# NANO103AE_v1 register map
File version: 1.0
Registers are 32-bit, read-write, reset 0x0 unless marked. A register's access mark holds for its fields unless they carry their own. Offsets are from the block's base; [hi:lo] are bit positions; lines under a group give offsets from that group; {n}, {i} and the like mark numbered series; 'fields as' and 'values as' point back to an identical list.

## PWM0 — PWM0 Register Map
Base 0x40040000
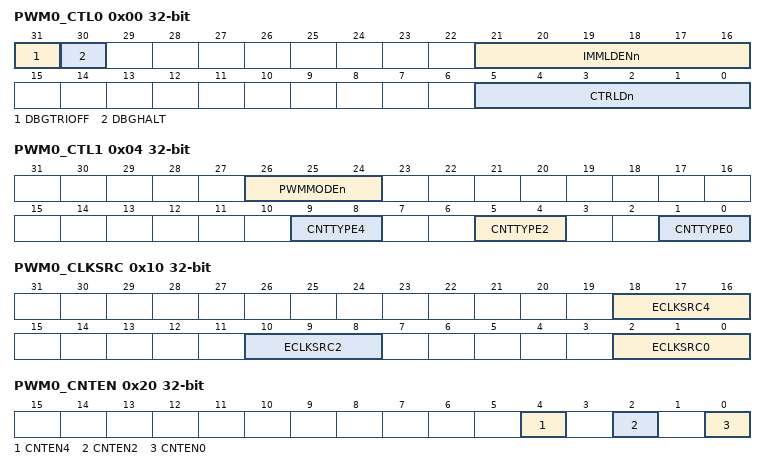
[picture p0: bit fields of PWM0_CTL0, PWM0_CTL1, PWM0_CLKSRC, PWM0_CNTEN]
0x00 PWM0_CTL0 — PWM0 Control Register 0
  [31] DBGTRIOFF — ICE Debug Mode Acknowledge Disable Bit (Write Protect). PWM0 pin will keep output no matter ICE debug mode acknowledged or not. Note: This bit is write protected. Refer toSYS_REGLCTL register.
    0=ICE debug mode acknowledgement effects PWM0 output; 1=ICE debug mode acknowledgement disabled
  [30] DBGHALT — ICE Debug Mode Counter Halt (Write Protect). If counter halt is enabled, PWM0 all counters will keep current value until exit ICE debug mode. Note:This bit is write protected. Refer toSYS_REGLCTL register.
    0=ICE debug mode counter halt Disabled; 1=ICE debug mode counter halt Enabled
  [21:16] IMMLDENn — Immediately Load Enable Bits. Each bit n controls the corresponding PWM0 channel n. Note: If IMMLDENn is enabled, WINLDENn and CTRLDn will be invalid.
    0=PERIOD will load to PBUF at the end point of each period. CMPDAT will load to CMPBUF at the end point or center point of each period by setting CTRLD bit; 1=PERIOD/CMPDAT will load to PBUF and CMPBUF immediately when software update PERIOD/CMPDAT
  [5:0] CTRLDn — Center Re-load. Each bit n controls the corresponding PWM0 channel n. In up-down counter type, PERIOD will load to PBUF at the end point of each period. CMPDAT will load to CMPBUF at the center point of a period.
0x04 PWM0_CTL1 — PWM0 Control Register 1
  [26:24] PWMMODEn — PWM0 Mode. Each bit n controls the corresponding PWM0 channel n. Note: When operating in group function, these bits must all set to the same mode.
    0=PWM0 independent mode; 1=PWM0 complementary mode
  [9:8] CNTTYPE4 — PWM0 Counter Behavior Type 4. Each bit n controls corresponding PWM0 channel n.
    0=Up counter type (supports in capture mode); 1=Down count type (supports in capture mode); 2=Up-down counter type
  [5:4] CNTTYPE2 — PWM0 Counter Behavior Type 2. Each bit n controls corresponding PWM0 channel n.
    values as CNTTYPE4
  [1:0] CNTTYPE0 — PWM0 Counter Behavior Type 0. Each bit n controls corresponding PWM0 channel n.
    values as CNTTYPE4
0x10 PWM0_CLKSRC — PWM0 Clock Source Register
  [all] fields
    0=PWMx_CLK, x denotes 0 or 1; {v}=TIMER{v-1} overflow (v=1..4)
  [18:16] ECLKSRC4 — PWM0_CH45 External Clock Source Select
  [10:8] ECLKSRC2 — PWM0_CH23 External Clock Source Select
  [2:0] ECLKSRC0 — PWM0_CH01 External Clock Source Select
0x14 PWM0_CLKPSC0_1 — PWM0 Clock Pre-Scale Register 0_1
  [11:0] CLKPSC — PWM0 Counter Clock Pre-scale. The clock of PWM0 counter is decided by clock prescaler. Each PWM0 pair share one PWM0 counter clock prescaler. The clock of PWM0 counter is divided by (CLKPSC+ 1).
0x18 PWM0_CLKPSC2_3 — PWM0 Clock Pre-Scale Register 2_3
  fields as PWM0_CLKPSC0_1
0x1C PWM0_CLKPSC4_5 — PWM0 Clock Pre-Scale Register 4_5
  fields as PWM0_CLKPSC0_1
0x20 PWM0_CNTEN — PWM0 Counter Enable Register
  [4] CNTEN4 — PWM0 Counter Enable Bit4
    0=PWM0 Counter4_5 and clock prescaler4 Stop Running. ....; 1=PWM0 Counter4_5 and clock prescaler4 Start Running
  [2] CNTEN2 — PWM0 Counter Enable Bit 2
    0=PWM0 Counter2_3 and clock prescaler2 Stop Running; 1=PWM0 Counter2_3 and clock prescaler2 Start Running
  [0] CNTEN0 — PWM0 Counter Enable Bit 0
    0=PWM0 Counter0_1 and clock prescaler0 Stop Running; 1=PWM0 Counter0_1 and clock prescaler0 Start Running
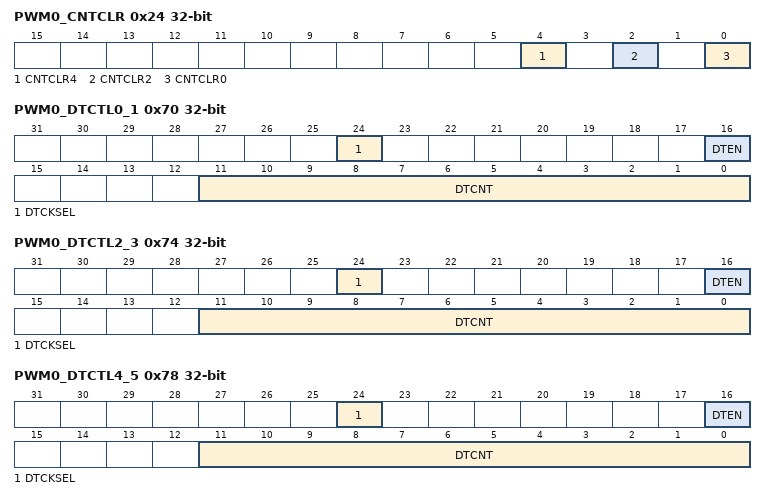
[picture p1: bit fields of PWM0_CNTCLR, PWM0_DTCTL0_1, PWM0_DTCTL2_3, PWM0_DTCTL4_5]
0x24 PWM0_CNTCLR — PWM0 Clear Counter Register
  [all] fields
    0=No effect; 1=Clear 16-bit PWM0 counter to 0000H
  [4] CNTCLR4 — Clear PWM0 Counter Control Bit 4. It is automatically cleared by hardware.
  [2] CNTCLR2 — Clear PWM0 Counter Control Bit 2. It is automatically cleared by hardware.
  [0] CNTCLR0 — Clear PWM0 Counter Control Bit 0. It is automatically cleared by hardware.
0x30 PWM0_PERIOD0 — PWM0 Period Register 0
  [15:0] PERIOD — PWM0 Period Register. Up-Count mode: In this mode, PWM0 counter counts from 0 to PERIOD, and restarts from 0. Down-Count mode: In this mode, PWM0 counter counts from PERIOD to 0, and restarts from PERIOD.
0x38 PWM0_PERIOD2 — PWM0 Period Register 2
  fields as PWM0_PERIOD0
0x40 PWM0_PERIOD4 — PWM0 Period Register 4
  fields as PWM0_PERIOD0
{0x50+4i} PWM0_CMPDAT{i} (i=0..5) — PWM0 Comparator Register {i}
  [15:0] CMPDAT — PWM0 Comparator Register. CMPDAT use to compare with CNTR to generate PWM0 waveform, interrupt and trigger ADC. In independent mode, CMPDAT0~5 denote as 6 independent PWM0_CH0~5 compared point. In complementary mode, CMPDAT0, 2, 4 denote as first compared point, and CMPDAT1, 3, 5 denote as second compared point for the corresponding 3 complementary pairs PWM0_CH0 and PWM0_CH1, PWM0_CH2 and PWM0_CH3, PWM0_CH4 and PWM0_CH5.
0x70 PWM0_DTCTL0_1 — PWM0 Dead-Time Control Register 0_1
  [24] DTCKSEL — Dead-time Clock Select (Write Protect). Note:This register is write protected. Refer toREGWRPROT register.
    0=Dead-time clock source from PWM0_CLKn; 1=Dead-time clock source from prescaler output
  [16] DTEN — Enable Dead-time Insertion for PWM0 Pair (PWM0_CH0, PWM0_CH1)(PWM0_CH2, PWM0_CH3)(PWM0_CH4, PWM0_CH5)(Write Protect). Dead-time insertion is only active when this PWM0 pair complementary mode is enabled. If dead- time insertion is inactive, the outputs of pin pair are complementary without any delay. Note:This register is write protected. Refer toSYS_REGLCTL register.
    0=Dead-time insertion Disabled on the pin pair; 1=Dead-time insertion Enabled on the pin pair
  [11:0] DTCNT — Dead-time Counter (Write Protect). The dead-time can be calculated from the following formula: Note:This register is write protected. Refer toSYS_REGLCTL register.
0x74 PWM0_DTCTL2_3 — PWM0 Dead-Time Control Register 2_3
  fields as PWM0_DTCTL0_1
0x78 PWM0_DTCTL4_5 — PWM0 Dead-Time Control Register 4_5
  fields as PWM0_DTCTL0_1
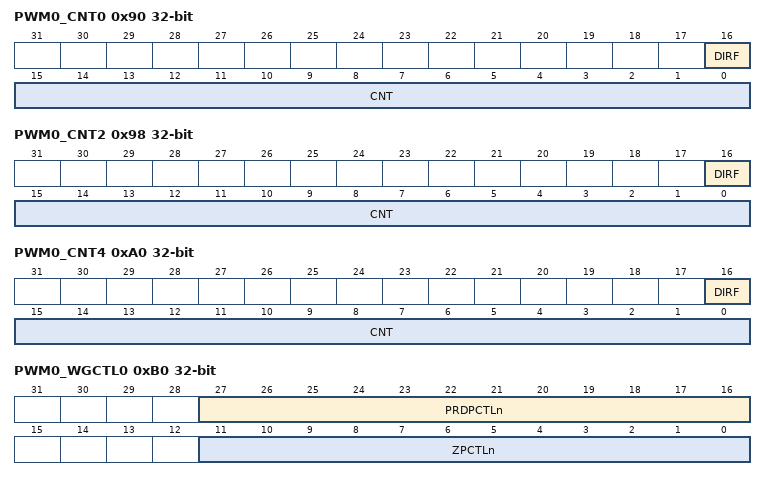
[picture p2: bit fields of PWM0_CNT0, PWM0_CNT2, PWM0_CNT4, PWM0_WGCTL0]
0x90 PWM0_CNT0 ro — PWM0 Counter Register 0
  [16] DIRF — PWM0 Direction Indicator Flag (Read Only)
    0=Counter is Down count; 1=Counter is UP count
  [15:0] CNT — PWM0 Data Register(Read Only). User can monitor CNTR to know the current value in 16-bit period counter.
0x98 PWM0_CNT2 ro — PWM0 Counter Register 2
  fields as PWM0_CNT0
0xA0 PWM0_CNT4 ro — PWM0 Counter Register 4
  fields as PWM0_CNT0
0xB0 PWM0_WGCTL0 — PWM0Waveform Generation Control Register 0
  [27:16] PRDPCTLn — PWM0 Period (Center) Point Control. Each bit n controls the corresponding PWM0 channel n. PWM0 can control output level when PWM0 counter count to (PERIODn+1). Note: This bit is center point control when PWM0 counter operating in up-down counter type.
    0=Do nothing; 1=PWM0 period (center) point output Low; 2=PWM0 period (center) point output High; 3=PWM0 period (center) point output Toggle
  [11:0] ZPCTLn — PWM0 Zero Point Control. Each bit n controls the corresponding PWM0 channel n. PWM0 can control output level when PWM0 counter count to zero.
    0=Do nothing; 1=PWM0 zero point output Low; 2=PWM0 zero point output High; 3=PWM0 zero point output Toggle
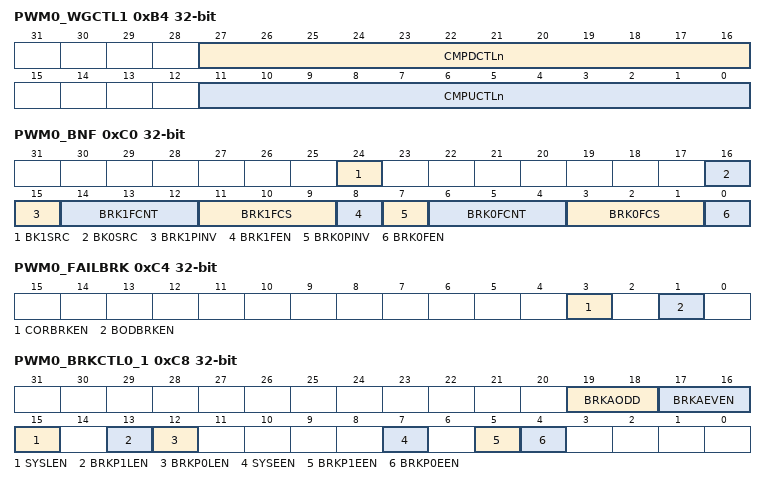
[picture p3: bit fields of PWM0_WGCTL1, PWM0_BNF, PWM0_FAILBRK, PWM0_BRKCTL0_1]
0xB4 PWM0_WGCTL1 — PWM0Waveform Generation Control Register 1
  [27:16] CMPDCTLn — PWM0 Compare Down Point Control. Each bit n controls the corresponding PWM0 channel n. PWM0 can control output level when PWM0 counter down count to CMPDAT. Note: In complementary mode, CMPDCTL1, 3, 5 use as another CMPDCTL for channel 0, 2, 4.
    0=Do nothing; 1=PWM0 compare down point output Low; 2=PWM0 compare down point output High; 3=PWM0 compare down point output Toggle
  [11:0] CMPUCTLn — PWM0 Compare Up Point Control. Each bit n controls the corresponding PWM0 channel n. PWM0 can control output level when PWM0 counter up count to CMPDAT. Note: In complementary mode, CMPUCTL1, 3, 5 use as another CMPUCTL for channel 0, 2, 4.
    0=Do nothing; 1=PWM0 compare up point output Low; 2=PWM0 compare up point output High; 3=PWM0 compare up point output Toggle
0xB8 PWM0_MSKEN — PWM0 Mask Enable Register
  [5:0] MSKENn — PWM0 Mask Enable Bits. Each bit n controls the corresponding PWM0 channel n. The PWM0 output signal will be masked when this bit is enabled. The corresponding PWM0 channel n will output MSKDATn (PWM0_MSK[5:0]) data.
    0=PWM0 output signal is non-masked; 1=PWM0 output signal is masked and output MSKDATn data
0xBC PWM0_MSK — PWM0 Mask Data Register
  [5:0] MSKDATn — PWM0 Mask Data Bits. This data bit control the state of PWM0_CHn output pin, if corresponding mask function is enabled.
    0=Output logic low to PWM0_CHn; 1=Output logic high to PWM0_CHn
0xC0 PWM0_BNF — PWM0 Brake Noise Filter Register
  [24] BK1SRC — Brake 1 Pin Source Select. For PWM0 setting:
    0=Brake 1 pin source come from PWM0_BRAKE1. Brake 1 pin source come from PWM1_BRAKE1; 1=Brake 1 pin source come from PWM1_BRAKE1. Brake 1 pin source come from PWM0_BRAKE1
  [16] BK0SRC — Brake 0 Pin Source Select. For PWM0 setting:
    0=Brake 0 pin source come from PWM0_BRAKE0. Brake 0 pin source come from PWM1_BRAKE0; 1=Brake 0 pin source come from PWM1_BRAKE0. Brake 0 pin source come from PWM0_BRAKE0
  [15] BRK1PINV — Brake 1 Pin Inverse
    0=The state of pin PWMx_BRAKE1 is passed to the negative edge detector; 1=The inversed state of pin PWMx_BRAKE1 is passed to the negative edge detector
  [14:12] BRK1FCNT — Brake 1 Edge Detector Filter Count. The register bits control the Brake1 filter counter to count from 0 to BRK1FCNT.
  [11:9] BRK1FCS — Brake 1 Edge Detector Filter Clock Selection
    0=Filter clock = HCLK; 1=Filter clock = HCLK/2; 2=Filter clock = HCLK/4; 3=Filter clock = HCLK/8; 4=Filter clock = HCLK/16; 5=Filter clock = HCLK/32; 6=Filter clock = HCLK/64; 7=Filter clock = HCLK/128
  [8] BRK1FEN — PWM0 Brake 1 Noise Filter Enable Bit
    0=Noise filter of PWM0 Brake 1 Disabled; 1=Noise filter of PWM0 Brake 1 Enabled
  [7] BRK0PINV — Brake 0 Pin Inverse
    0=The state of pin PWMx_BRAKE0 is passed to the negative edge detector; 1=The inversed state of pin PWMx_BRAKE10 is passed to the negative edge detector
  [6:4] BRK0FCNT — Brake 0 Edge Detector Filter Count. The register bits control the Brake0 filter counter to count from 0 to BRK1FCNT.
  [3:1] BRK0FCS — Brake 0 Edge Detector Filter Clock Selection
    values as BRK1FCS
  [0] BRK0FEN — PWM0 Brake 0 Noise Filter Enable Bit
    0=Noise filter of PWM0 Brake 0 Disabled; 1=Noise filter of PWM0 Brake 0 Enabled
0xC4 PWM0_FAILBRK — PWM0 System Fail Brake Control Register
  [3] CORBRKEN — Core Lockup Detection Trigger PWM0 Brake Function 0 Enable Bit
    0=Brake Function triggered by Core lockup detection Disabled; 1=Brake Function triggered by Core lockup detection Enabled
  [1] BODBRKEN — Brown-out Detection Trigger PWM0 Brake Function 0 Enable Bit
    0=Brake Function triggered by BOD Disabled; 1=Brake Function triggered by BOD Enabled
0xC8 PWM0_BRKCTL0_1 — PWM0 Brake Edge Detect Control Register 0_1
  [19:18] BRKAODD — PWM0 Brake Action Select for Odd Channel (Write Protect). Note: This register is write protected. Refer toSYS_REGLCTL register.
    0=PWM0 odd channel brake function not affect channel output; 1=PWM0 odd channel output tri-state when brake happened; 2=PWM0 odd channel output low level whenbrake happened; 3=PWM0 odd channel output high level when brake happened
  [17:16] BRKAEVEN — PWM0 Brake Action Select for Even Channel (Write Protect). Note: This register is write protected. Refer toSYS_REGLCTL register.
    0=PWM0 even channelbrake function not affect channel output; 1=PWM0 even channel output tri-state when brake happened; 2=PWM0 even channel output low level whenbrake happened; 3=PWM0 even channel output high level when brake happened
  [15] SYSLEN — Enable System Fail As Level-detect Brake Source(Write Protect). Note: This register is write protected. Refer toSYS_REGLCTL register.
    0=System Fail condition as level-detect brake source Disabled; 1=System Fail condition as level-detect brake source Enabled
  [13] BRKP1LEN — Enable BKP1 Pin As Level-detect Brake Source(Write Protect). Note: This register is write protected. Refer toSYS_REGLCTL register.
    0=PWMx_BRAKE1 pin as level-detect brake source Disabled; 1=PWMx_BRAKE1 pin as level-detect brake source Enabled
  [12] BRKP0LEN — Enable BKP0 Pin As Level-detect Brake Source(Write Protect). Note: This register is write protected. Refer toSYS_REGLCTL register.
    0=PWMx_BRAKE0 pin as level-detect brake source Disabled; 1=PWMx_BRAKE0 pin as level-detect brake source Enabled
  [7] SYSEEN — Enable System Fail As Edge-detect Brake Source(Write Protect). Note: This register is write protected. Refer toSYS_REGLCTL register.
    0=System Fail condition as edge-detect brake source Disabled; 1=System Fail condition as edge-detect brake source Enabled
  [5] BRKP1EEN — Enable PWMx_BRAKE1 Pin As Edge-detect Brake Source(Write Protect). Note: This register is write protected. Refer toSYS_REGLCTL register.
    0=BKP1 pin as edge-detect brake source Disabled; 1=BKP1 pin as edge-detect brake source Enabled
  [4] BRKP0EEN — Enable PWMx_BRAKE0 Pin As Edge-detect Brake Source(Write Protect). Note: This register is write protected. Refer toSYS_REGLCTL register.
    0=BKP0 pin as edge-detect brake source Disabled; 1=BKP0 pin as edge-detect brake source Enabled
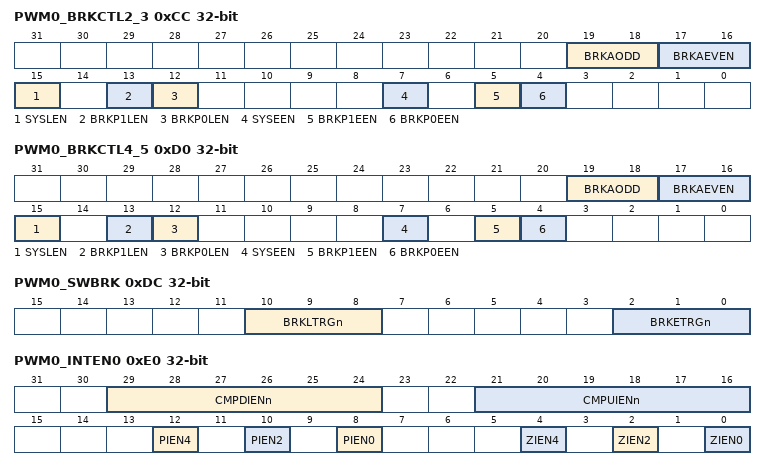
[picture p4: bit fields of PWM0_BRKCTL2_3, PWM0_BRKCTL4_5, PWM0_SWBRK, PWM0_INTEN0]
0xCC PWM0_BRKCTL2_3 — PWM0 Brake Edge Detect Control Register 2_3
  fields as PWM0_BRKCTL0_1
0xD0 PWM0_BRKCTL4_5 — PWM0 Brake Edge Detect Control Register 4_5
  fields as PWM0_BRKCTL0_1
0xD4 PWM0_POLCTL — PWM0 Pin Polar Inverse Register
  [5:0] PINVn — PWM0 PIN Polar Inverse Control. The register controls polarity state of PWM0 output. Each bit n controls the corresponding PWM0 channel n.
    0=PWM0 output polar inverse Disabled; 1=PWM0 output polar inverse Enabled
0xD8 PWM0_POEN — PWM0 Output Enable Register
  [5:0] POENn — PWM0 Pin Output Enable Bits. Each bit n controls the corresponding PWM0 channel n.
    0=PWM0 pin at tri-state; 1=PWM0 pin in output mode
0xDC PWM0_SWBRK wo — PWM0 Software Brake Control Register
  [10:8] BRKLTRGn — PWM0 Level Brake Software Trigger (Write Only)(Write Protect). Each bit n controls the corresponding PWM0 pair n. Write 1 to this bit will trigger level brake, and set BRKLIFn to 1 in PWM0_INTSTS1 register. Note:This register is write protected. Refer toSYS_REGLCTL register.
  [2:0] BRKETRGn — PWM0 Edge Brake Software Trigger (Write Only)(Write Protect). Each bit n controls the corresponding PWM0 pair n. Write 1 to this bit will trigger Edge brake, and set BRKEIFn to 1 in PWM0_INTSTS1 register. Note:This register is write protected. Refer toSYS_REGLCTL register.
0xE0 PWM0_INTEN0 — PWM0 Interrupt Enable Register 0
  [29:24] CMPDIENn — PWM0 Compare Down Count Interrupt Enable Bits. Each bit n controls the corresponding PWM0 channel n. Note: In complementary mode, CMPDIEN1, 3, 5 use as another CMPDIEN for channel 0, 2, 4.
    0=Compare down count interrupt Disabled; 1=Compare down count interrupt Enabled
  [21:16] CMPUIENn — PWM0 Compare Up Count Interrupt Enable Bits. Each bit n controls the corresponding PWM0 channel n. Note: In complementary mode, CMPUIEN1, 3, 5 use as another CMPUIEN for channel 0, 2, 4.
    0=Compare up count interrupt Disabled; 1=Compare up count interrupt Enabled
  [12] PIEN4 — PWM0 Period Point Interrupt Enable Bit 4. Note: When operating in up-down counter type, period point means center point.
    0=PWM0counter4_5 period point interrupt Disabled; 1=PWM0counter4_5 period point interrupt Enabled
  [10] PIEN2 — PWM0 Period Point Interrupt Enable Bit 2. Note: When operating in up-down counter type, period point means center point.
    0=PWM0counter2_3 period point interrupt Disabled; 1=PWM0counter2_3 period point interrupt Enabled
  [8] PIEN0 — PWM0 Period Point Interrupt Enable Bit 0. Note: When operating in up-down counter type, period point means center point.
    0=PWM0counter0_1 period point interrupt Disabled; 1=PWM0counter0_1 period point interrupt Enabled
  [4] ZIEN4 — PWM0 Zero Point Interrupt Enable Bit 4. Note: Odd channels will read always 0 at complementary mode.
    0=PWM0counter4_5 zero point interrupt Disabled; 1=PWM0counter4_5 zero point interrupt Enabled
  [2] ZIEN2 — PWM0 Zero Point Interrupt Enable Bit 2. Note: Odd channels will read always 0 at complementary mode.
    0=PWM0counter2_3 zero point interrupt Disabled; 1=PWM0counter2_3 zero point interrupt Enabled
  [0] ZIEN0 — PWM0 Zero Point Interrupt Enable Bit 0. Note: Odd channels will read always 0 at complementary mode.
    0=PWM0counter0_1 zero point interrupt Disabled; 1=PWM0counter0_1 zero point interrupt Enabled
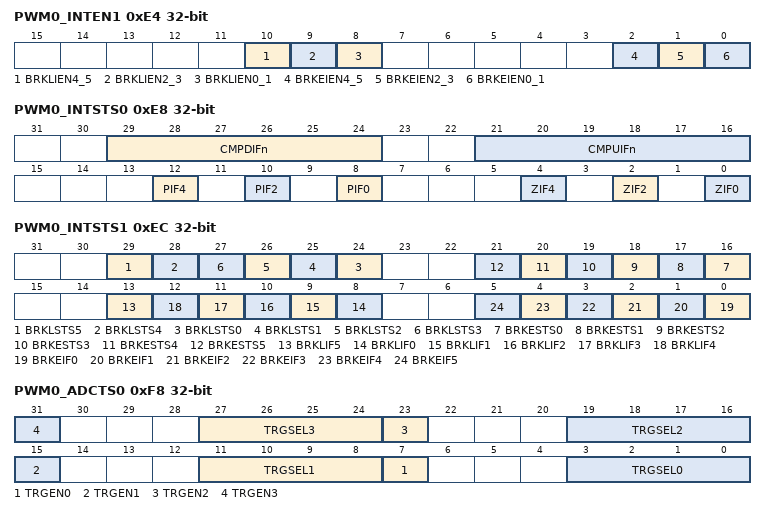
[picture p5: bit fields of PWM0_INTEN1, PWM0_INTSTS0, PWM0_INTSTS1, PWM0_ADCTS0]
0xE4 PWM0_INTEN1 — PWM0 Interrupt Enable Register 1
  [10] BRKLIEN4_5 — PWM0 Level-detect Brake Interrupt Enable Bit for Channel4/5(Write Protect). Note: This register is write protected. Refer toSYS_REGLCTL register.
    0=Level-detect Brake interrupt for channel4/5 Disabled; 1=Level-detect Brake interrupt for channel4/5 Enabled
  [9] BRKLIEN2_3 — PWM0 Level-detect Brake Interrupt Enable Bitfor Channel2/3(Write Protect). Note: This register is write protected. Refer toSYS_REGLCTL register.
    0=Level-detect Brake interrupt for channel2/3 Disabled; 1=Level-detect Brake interrupt for channel2/3 Enabled
  [8] BRKLIEN0_1 — PWM0 Level-detect Brake Interrupt Enable Bitfor Channel0/1(Write Protect). Note: This register is write protected. Refer toSYS_REGLCTL register.
    0=Level-detect Brake interrupt for channel0/1 Disabled; 1=Level-detect Brake interrupt for channel0/1 Enabled
  [2] BRKEIEN4_5 — PWM0 Edge-detect Brake Interrupt Enable Bitfor Channel4/5(Write Protect). Note: This register is write protected. Refer toSYS_REGLCTL register.
    0=Edge-detect Brake interrupt for channel4/5 Disabled; 1=Edge-detect Brake interrupt for channel4/5 Enabled
  [1] BRKEIEN2_3 — PWM0 Edge-detect Brake Interrupt Enable Bitfor Channel2/3(Write Protect). Note: This register is write protected. Refer toSYS_REGLCTL register.
    0=Edge-detect Brake interrupt for channel2/3 Disabled; 1=Edge-detect Brake interrupt for channel2/3 Enabled
  [0] BRKEIEN0_1 — PWM0 Edge-detect Brake Interrupt Enable Bitfor Channel0/1(Write Protect). Note: This register is write protected. Refer toSYS_REGLCTL register.
    0=Edge-detect Brake interrupt for channel0/1 Disabled; 1=Edge-detect Brake interrupt for channel0/1 Enabled
0xE8 PWM0_INTSTS0 — PWM0 Interrupt Flag Register 0
  [29:24] CMPDIFn — PWM0 Compare Down Count Interrupt Flag. Each bit n controls the corresponding PWM0 channel n. Flag is set by hardware when PWM0 counter down count and reaches PWM0_CMPDATn, software can clear this bit by writing 1 to it. Note1: If CMPDAT equal to PERIOD, this flag is not working in down counter type selection. Note2: In complementary mode, CMPDIF1, 3, 5 use as another CMPDIF for channel 0, 2, 4.
  [21:16] CMPUIFn — PWM0 Compare Up Count Interrupt Flag. Flag is set by hardware when PWM0 counter up count and reaches PWM0_CMPDATn, software can clear this bit by writing 1 to it. Each bit n controls the corresponding PWM0 channel n. Note1: If CMPDAT equal to PERIOD, this flag is not working in up counter type selection. Note2: In complementary mode, CMPUIF1, 3, 5 use as another CMPUIF for channel 0, 2, 4.
  [12] PIF4 — PWM0 Period Point Interrupt Flag 4. This bit is set by hardware when PWM0_CH4 counter reaches PWM0_PERIOD4, software can write 1 to clear this bit to zero.
  [10] PIF2 — PWM0 Period Point Interrupt Flag 2. This bit is set by hardware when PWM0_CH2 counter reaches PWM0_PERIOD2, software can write 1 to clear this bit to zero.
  [8] PIF0 — PWM0 Period Point Interrupt Flag 0. This bit is set by hardware when PWM0_CH0 counter reaches PWM0_PERIOD0, software can write 1 to clear this bit to zero.
  [4] ZIF4 — PWM0 Zero Point Interrupt Flag 4. This bit is set by hardware when PWM0_CH4 counter reaches zero, software can write 1 to clear this bit to zero.
  [2] ZIF2 — PWM0 Zero Point Interrupt Flag 2. This bit is set by hardware when PWM0_CH2 counter reaches zero, software can write 1 to clear this bit to zero.
  [0] ZIF0 — PWM0 Zero Point Interrupt Flag 0. This bit is set by hardware when PWM0_CH0 counter reaches zero, software can write 1 to clear this bit to zero.
0xEC PWM0_INTSTS1 — PWM0 Interrupt Flag Register 1
  [29] BRKLSTS5 ro — PWM0 Channel5 Level-detect Brake Status (Read Only). Note: This bit is read only and auto cleared by hardware. When enabled brake source return to high level, PWM0 will release brake state until current PWM0 period finished. The PWM0 waveform will start output from next full PWM0 period.
    0=PWM0 channel5 level-detect brake state is released; 1=When PWM0 channel5 level-detect brake detects a falling edge of any enabled brake source; this flag will be set to indicate the PWM0 channel5 at brake state
  [28] BRKLSTS4 ro — PWM0 Channel4 Level-detect Brake Status (Read Only). Note: This bit is read only and auto cleared by hardware. When enabled brake source return to high level, PWM0 will release brake state until current PWM0 period finished. The PWM0 waveform will start output from next full PWM0 period.
    0=PWM0 channel4 level-detect brake state is released; 1=When PWM0 channel4 level-detect brake detects a falling edgeof any enabled brake source; this flag will be set to indicate the PWM0 channel4 at brake state
  [n+24] BRKLSTS{n} ro (n=0..3) — PWM0 Channel{n} Level-detect Brake Status (Read Only). Note: This bit is read only and auto cleared by hardware. When enabled brake source return to high level, PWM0 will release brake state until current PWM0 period finished. The PWM0 waveform will start output from next full PWM0 period.
    0=PWM0 channel{n} level-detect brake state is released; 1=When PWM0 channel{n} level-detect brake detects a falling edge of any enabled brake source; this flag will be set to indicate the PWM0 channel{n} at brake state
  [n+16] BRKESTS{n} ro (n=0..5) — PWM0 Channel{n} Edge-detect Brake Status (Read Only)
    0=PWM0 channel{n} edge-detect brake state is released; 1=When PWM0 channel{n} edge-detect brake detects a falling edge of any enabled brake source; this flag will be set to indicate the PWM0 channel{n} at brake state, writing 1 to clear
  [13] BRKLIF5 — PWM0 Channel5 Level-detect Brake Interrupt Flag(Write Protect). Note: This bit is write protected. Refer toSYS_REGLCTL register.
    0=PWM0 channel5 level-detect brake event do not happened; 1=When PWM0 channel5 level-detect brake event happened, this bit is set to 1, writing 1 to clear
  [n+8] BRKLIF{n} (n=0..4) — PWM0 Channel{n} Level-detect Brake Interrupt Flag (Write Protect). Note: This bit is write protected. Refer toSYS_REGLCTL register.
    0=PWM0 channel{n} level-detect brake event do not happened; 1=When PWM0 channel{n} level-detect brake event happened, this bit is set to 1, writing 1 to clear
  [n] BRKEIF{n} (n=0..5) — PWM0 Channel{n} Edge-detect Brake Interrupt Flag (Write Protect). Note: This bit is write protected. Refer toSYS_REGLCTL register.
    0=PWM0 channel{n} edge-detect brake event do not happened; 1=When PWM0 channel{n} edge-detect brake event happened, this bit is set to 1, writing 1 to clear
0xF8 PWM0_ADCTS0 — PWM0 Trigger ADC Source Select Register 0
  [8n+7] TRGEN{n} (n=0..3) — PWM0_CH{n} Trigger EADC Enable Bit
    0=PWM0_CH{n} Trigger EADC Disabled; 1=PWM0_CH{n} Trigger EADC Enabled
  [27:24] TRGSEL3 — PWM0_CH3 Trigger ADC Source Select. Others reserved
    0=PWM0_CH2 zero point; 1=PWM0_CH2 period point; 2=PWM0_CH2 zero or period point; 3=PWM0_CH2 up-count CMPDAT point; 4=PWM0_CH2 down-count CMPDAT point; 8=PWM0_CH3 up-count CMPDAT point; 9=PWM0_CH3 down-count CMPDAT point
  [19:16] TRGSEL2 — PWM0_CH2 Trigger ADC Source Select. Others reserved
    values as TRGSEL3
  [11:8] TRGSEL1 — PWM0_CH1 Trigger ADC Source Select. Others reserved
    0=PWM0_CH0 zero point; 1=PWM0_CH0 period point; 2=PWM0_CH0 zero or period point; 3=PWM0_CH0 up-count CMPDAT point; 4=PWM0_CH0 down-count CMPDAT point; 8=PWM0_CH1 up-count CMPDAT point; 9=PWM0_CH1 down-count CMPDAT point
  [3:0] TRGSEL0 — PWM0_CH0 Trigger ADC Source Select. Others reserved
    values as TRGSEL1
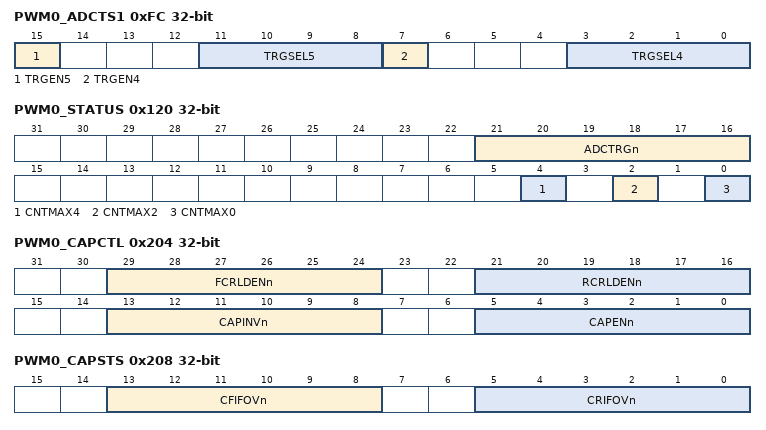
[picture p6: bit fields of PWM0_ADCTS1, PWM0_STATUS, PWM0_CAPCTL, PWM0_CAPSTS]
0xFC PWM0_ADCTS1 — PWM0 Trigger ADC Source Select Register 1
  [15] TRGEN5 — PWM0_CH5 Trigger EADC Enable Bit
    0=PWM0_CH5 Trigger EADC Disabled; 1=PWM0_CH5 Trigger EADC Enabled
  [11:8] TRGSEL5 — PWM0_CH5 Trigger ADC Source Select. Others reserved
    0=PWM0_CH4 zero point; 1=PWM0_CH4 period point; 2=PWM0_CH4 zero or period point; 3=PWM0_CH4 up-count CMPDAT point; 4=PWM0_CH4 down-count CMPDAT point; 8=PWM0_CH5 up-count CMPDAT point; 9=PWM0_CH5 down-count CMPDAT point
  [7] TRGEN4 — PWM0_CH4 Trigger EADC Enable Bit
    0=PWM0_CH4 Trigger EADC Disabled; 1=PWM0_CH4 Trigger EADC Enabled
  [3:0] TRGSEL4 — PWM0_CH4 Trigger ADC Source Select. Others reserved
    values as TRGSEL5
0x120 PWM0_STATUS
  [21:16] ADCTRGn — ADC Start of Conversion Status. Each bit n controls the corresponding PWM0 channel n.
    0=Indicates no ADC start of conversion trigger event has occurred; 1=Indicates an ADC start of conversion trigger event has occurred, software can write 1 to clear this bit
  [4] CNTMAX4 — Time-base Counter 4 Equal to 0xFFFF Latched Status
    0=indicates the time-base counter never reached its maximum value 0xFFFF; 1=indicates the time-base counter reached its maximum value, software can write 1 to clear this bit
  [2] CNTMAX2 — Time-base Counter 2 Equal to 0xFFFF Latched Status
    values as CNTMAX4
  [0] CNTMAX0 — Time-base Counter 0 Equal to 0xFFFF Latched Status
    values as CNTMAX4
0x200 PWM0_CAPINEN — PWM0 Capture Input Enable Register
  [5:0] CAPINENn — Capture Input Enable Bits. Each bit n controls the corresponding PWM0 channel n.
    0=PWM0 Channel capture input path Disabled. The input of PWM0 channel capture function is always regarded as 0; 1=PWM0 Channel capture input path Enabled. The input of PWM0 channel capture function comes from correlative multifunction pin
0x204 PWM0_CAPCTL — PWM0 Capture Control Register
  [29:24] FCRLDENn — Falling Capture Reload EnableBits. Each bit n controls the corresponding PWM0 channel n.
    0=Falling capture reload counter Disabled; 1=Falling capture reload counter Enabled
  [21:16] RCRLDENn — Rising Capture Reload Enable Bits. Each bit n controls the corresponding PWM0 channel n.
    0=Risingcapture reload counter Disabled; 1=Risingcapture reload counter Enabled
  [13:8] CAPINVn — Capture Inverter Enable Bits. Each bit n controls the corresponding PWM0 channel n.
    0=Capture source inverter Disabled; 1=Capture source inverter Enabled. Reverse the input signal from GPIO
  [5:0] CAPENn — Capture Function Enable Bits. Each bit n controls the corresponding PWM0 channel n.
    0=Capture function Disabled. RCAPDAT/FCAPDAT register will not be updated; 1=Capture function Enabled. Capture latched the PWM0 counter value when detected rising or falling edge of input signal and saved to RCAPDAT (Rising latch) and FCAPDAT (Falling latch)
0x208 PWM0_CAPSTS ro — PWM0 Capture Status Register
  [13:8] CFIFOVn — Capture Falling Interrupt Flag Overrun Status(Read Only). This flag indicatesif falling latch happenedwhen the corresponding CAPFIFis 1. Each bit n controls the corresponding PWM0 channel n. Note:This bit will be cleared automatically when user clear corresponding CAPFIF.
  [5:0] CRIFOVn — Capture Rising Interrupt Flag Overrun Status(Read Only). This flag indicatesif rising latch happenedwhen the corresponding CAPRIFis 1. Each bit n controls the corresponding PWM0 channel n. Note:This bit will be cleared automatically when user clear corresponding CAPRIF.
{0x20C+8i} PWM0_RCAPDAT{i} ro (i=0..5) — PWM0 Rising Capture Data Register {i}
  [15:0] RCAPDAT — PWM0 Rising Capture Data Register(Read Only). When rising capture condition happened, the PWM0 counter value will be saved in this register.
{0x210+8i} PWM0_FCAPDAT{i} ro (i=0..5) — PWM0 Falling Capture Data Register {i}
  [15:0] FCAPDAT — PWM0 Falling Capture Data Register(Read Only). When falling capture condition happened, the PWM0 counter value will be saved in this register.
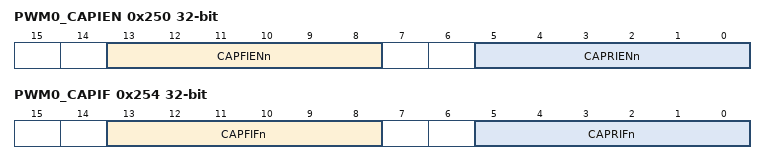
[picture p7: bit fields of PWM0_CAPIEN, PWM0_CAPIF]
0x250 PWM0_CAPIEN — PWM0 Capture Interrupt Enable Register
  [13:8] CAPFIENn — PWM0 Capture Falling Latch Interrupt Enable Bits. Each bit n controls the corresponding PWM0 channel n.
    0=Capture falling edge latch interrupt Disabled; 1=Capture falling edge latch interrupt Enabled
  [5:0] CAPRIENn — PWM0 Capture Rising Latch Interrupt Enable Bits. Each bit n controls the corresponding PWM0 channel n.
    0=Capture rising edge latch interrupt Disabled; 1=Capture rising edge latch interrupt Enabled
0x254 PWM0_CAPIF — PWM0 Capture Interrupt Flag Register
  [13:8] CAPFIFn — PWM0 Capture Falling Latch Interrupt Flag. This bit is writing 1 to clear. Each bit n controls the corresponding PWM0 channel n.
    0=No capture falling latch condition happened; 1=Capture falling latch condition happened, this flag will be set to high
  [5:0] CAPRIFn — PWM0 Capture Rising Latch Interrupt Flag. This bit is writing 1 to clear. Each bit n controls the corresponding PWM0 channel n.
    0=No capture rising latch condition happened; 1=Capture rising latch condition happened, this flag will be set to high
0x300 PWM0_SELFTEST — PWM0 Self-test Mode Enable
0x304 PWM0_PBUF0 ro — PWM0 PERIOD0 Buffer
  [15:0] PBUF — PWM0 Period Register Buffer(Read Only). Used as PERIOD active register.
0x30C PWM0_PBUF2 ro — PWM0 PERIOD2 Buffer
  fields as PWM0_PBUF0
0x314 PWM0_PBUF4 ro — PWM0 PERIOD4 Buffer
  fields as PWM0_PBUF0
{0x31C+4i} PWM0_CMPBUF{i} ro (i=0..5) — PWM0 CMPDAT{i} Buffer
  [15:0] CMPBUF — PWM0 Comparator Register Buffer(Read Only). Used as CMP active register.
0xFFC PWM0_VERSION ro reset 0x2010000 — PWM0 RTL Design Version Number
